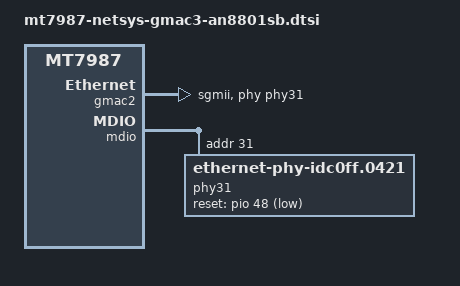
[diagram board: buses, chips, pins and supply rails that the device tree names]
// SPDX-License-Identifier: (GPL-2.0 OR MIT)

&gmac2 {
	mac-type = "gdm";
	phy-mode = "sgmii";
	phy-handle = <&phy31>;
};

&mdio {
	/delete-property/ reset-gpios;
	/delete-property/ reset-delay-us;
	/delete-node/ phy@11;
	phy31: phy@31 {
		compatible = "ethernet-phy-idc0ff.0421";
		reg = <31>;
		reset-gpios = <&pio 48 1>;
		reset-assert-us = <10000>;
		reset-deassert-us = <10000>;
		phy-mode = "sgmii";
	};
};
